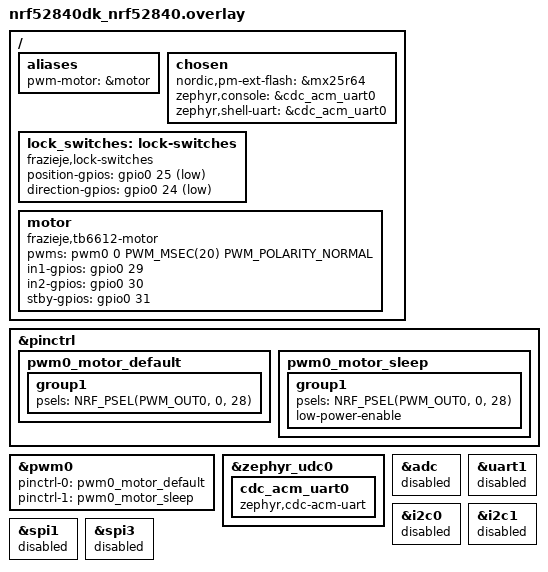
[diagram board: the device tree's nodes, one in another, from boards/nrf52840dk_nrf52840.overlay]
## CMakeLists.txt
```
#
# Copyright (c) 2021 Nordic Semiconductor ASA
#
# SPDX-License-Identifier: LicenseRef-Nordic-5-Clause
#

cmake_minimum_required(VERSION 3.20.0)

find_package(Zephyr REQUIRED HINTS $ENV{ZEPHYR_BASE})
project(farlock3)

# Enable GNU STD support.
include(${ZEPHYR_CONNECTEDHOMEIP_MODULE_DIR}/config/nrfconnect/app/enable-gnu-std.cmake)

# NORDIC SDK APP START

# Include all source files that are located in the Matter common directory.
include(${ZEPHYR_NRF_MODULE_DIR}/samples/matter/common/cmake/source_common.cmake)

# Include Data Model utils
include(${ZEPHYR_NRF_MODULE_DIR}/samples/matter/common/cmake/data_model.cmake)

include(${ZEPHYR_NRF_MODULE_DIR}/samples/matter/common/cmake/zap_helpers.cmake)
ncs_get_zap_parent_dir(ZAP_PARENT_DIR)

target_include_directories(app PRIVATE
  src
  ${ZAP_PARENT_DIR}
)

target_sources(app PRIVATE
  src/main.cpp
  src/app_task.cpp
  src/bolt_lock_manager.cpp
  src/indication.cpp
  src/zcl_callbacks.cpp
  src/nfc.c
  src/ndef_storage.c
  src/access/access_data_types.cpp
  src/access/access_manager_credentials.cpp
  src/access/access_manager_users.cpp
  src/access/access_manager.cpp
)

if(NOT CONFIG_FARLOCK3_LOCK_SIMULATED)
  target_sources(app PRIVATE src/lock_hw.c)
endif()

target_sources_ifdef(CONFIG_FARLOCK3_USB_CONSOLE app PRIVATE
  src/usb.c
)

target_sources_ifdef(CONFIG_SHELL app PRIVATE
  src/lock_shell.cpp
)

target_sources_ifdef(CONFIG_LOCK_ACCESS_STORAGE_PERSISTENT_STORAGE app PRIVATE
  src/access/access_storage.cpp
)

target_sources_ifdef(CONFIG_LOCK_ACCESS_STORAGE_PROTECTED_STORAGE app PRIVATE
  src/access/access_storage_psa_ps.cpp
)

target_sources_ifdef(CONFIG_LOCK_SCHEDULES app PRIVATE
  src/access/access_manager_schedules.cpp
)

target_sources_ifdef(CONFIG_LOCK_PRINT_STORAGE_STATUS app PRIVATE
  src/access/access_storage_print.cpp
)

# Do not treat warnings as errors while the variable may be uninitialized for this sample data model.
# In the door-lock-server implementation, there is a warning that the C++ "optional"
# variable may be uninitialized, but actually, it is wrongly interpreted by the Zephyr toolchain.
target_compile_options(matter-data-model PRIVATE -Wno-error=maybe-uninitialized)

ncs_configure_data_model()

# NORDIC SDK APP END
```

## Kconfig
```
#
# Copyright (c) 2021 Nordic Semiconductor
#
# SPDX-License-Identifier: LicenseRef-Nordic-5-Clause
#

mainmenu "FARLock v3 Matter door lock"

menu "FARLock hardware"

config FARLOCK3_LOCK_SIMULATED
	bool "Simulate the bolt (no motor or switches)"
	help
	  Build without the motor driver and switch handling. Lock and unlock
	  actions complete after a fixed delay. Useful on development kits
	  without the mechanism attached. When disabled, the board must provide
	  "frazieje,tb6612-motor" and "frazieje,lock-switches" devicetree nodes.

if !FARLOCK3_LOCK_SIMULATED

config FARLOCK3_MOTOR_TIMEOUT_MS
	int "Maximum motor run time in milliseconds"
	default 3000
	help
	  The motor is stopped when the bolt position switch changes. If that
	  has not happened after this many milliseconds the motor is stopped
	  anyway and a LockJammed alarm is raised.

config FARLOCK3_MOTOR_DUTY_CYCLE
	int "Motor PWM duty cycle in percent"
	range 1 100
	default 100

config FARLOCK3_SWITCH_DEBOUNCE_MS
	int "Position switch debounce time in milliseconds"
	default 20

endif # !FARLOCK3_LOCK_SIMULATED

config FARLOCK3_USB_CONSOLE
	bool "USB CDC ACM console"
	default y
	depends on USB_DEVICE_STACK_NEXT && USBD_CDC_ACM_CLASS
	help
	  Bring up the USB device stack at boot so that the console and shell
	  are available over the micro-B port when a host is attached.

if FARLOCK3_USB_CONSOLE

config FARLOCK3_USBD_VID
	hex "USB vendor ID"
	default 0x1915

config FARLOCK3_USBD_PID
	hex "USB product ID"
	default 0x0004

config FARLOCK3_USBD_MANUFACTURER
	string "USB manufacturer string"
	default "frazieje"

config FARLOCK3_USBD_PRODUCT
	string "USB product string"
	default "FARLock v3"

config FARLOCK3_USBD_SELF_POWERED
	bool "USB self-powered attribute"
	default y

config FARLOCK3_USBD_REMOTE_WAKEUP
	bool "USB remote wakeup attribute"
	default n

config FARLOCK3_USBD_MAX_POWER
	int "USB maximum power in 2 mA units"
	default 125
	range 0 250

config FARLOCK3_USBD_20_EXTENSION_DESC
	bool "Use default USB 2.0 Extension Descriptor"
	depends on USBD_BOS_SUPPORT

endif # FARLOCK3_USB_CONSOLE

endmenu

menu "Door lock cluster"

config LOCK_MAX_NUM_USERS
	int "Maximum number of users supported by the lock"
	default 10

config LOCK_MAX_NUM_CREDENTIALS_PER_USER
	int "Maximum total number of credentials per one user supported by the lock"
	default 4

config LOCK_MAX_NUM_CREDENTIALS_PER_TYPE
	int "Maximum number of credentials of given type supported by the lock"
	default 15

config LOCK_MAX_CREDENTIAL_LENGTH
	int "Maximum length of the single credential supported by the lock"
	default 10

config LOCK_PASS_CREDENTIALS_TO_SET_LOCK_STATE
	bool "Pass used credentials when setting the lock state"
	help
	  This option should stay disabled until TC-DRLK-2.3 is fixed.
	  Related issue: https://github.com/project-chip/connectedhomeip/issues/38222

config LOCK_SCHEDULES
	bool "Support for WeekDay, YearDay and Holiday schedules in lock"
	help
	  This option adds support for an optional Timed Schedule Access Lock feature.
	  You can use Week Day, Year Day and Holiday schedules to restrict access for a
	  specific user for a defined time window. For example, use it to
	  give the user access only for three days in week.

if LOCK_SCHEDULES

config LOCK_MAX_WEEKDAY_SCHEDULES_PER_USER
	int "Maximum number of WeekDay schedules per one user supported by the lock"
	default 5

config LOCK_MAX_YEARDAY_SCHEDULES_PER_USER
	int "Maximum number of YearDay schedules per one user supported by the lock"
	default 5

config LOCK_MAX_HOLIDAY_SCHEDULES
	int "Maximum number of Holiday schedules supported by the lock"
	default 5

endif

config LOCK_ENABLE_DEBUG
	bool "Debug features to print users and credentials"
	depends on SHELL
	help
	  Debug features allows to checking and printing current users, their state, and
	  associated credentials. Use these with shell commands combinations to read saved credentials
	  or users, and manage them (add, clear, read).

if LOCK_ENABLE_DEBUG

config LOCK_PRINT_STORAGE_STATUS
	bool "Print storage status after each store call"
	# This feature assumes that items are eventually stored in Zephyr settings subsystem
	depends on LOCK_ACCESS_STORAGE_PERSISTENT_STORAGE || TRUSTED_STORAGE_STORAGE_BACKEND_SETTINGS
	help
	  Debug feature to print the debug-level log that contains information of the entry being stored
	  to persistent storage and how many bytes are left to store the new entry. It can be used to verify
	  whether credential, schedule or user entries are written properly to persistent storage.
	  This option should be disabled in production firmware
	  version.

# This should be deterined based on the maximum possible command length that depends on the LOCK_MAX_CREDENTIAL_LENGTH
config SHELL_CMD_BUFF_SIZE
	default 300

endif

choice LOCK_ACCESS_STORAGE_CHOICE
	prompt "Access storage implementation"
	default LOCK_ACCESS_STORAGE_PROTECTED_STORAGE

config LOCK_ACCESS_STORAGE_PERSISTENT_STORAGE
	bool "Persistent storage interface"
	select NCS_SAMPLE_MATTER_PERSISTENT_STORAGE

config LOCK_ACCESS_STORAGE_PROTECTED_STORAGE
	bool "PSA Protected Storage"
	# PSA SSF Crypto Client is not ready for PSA PS backend
	depends on !CHIP_WIFI && !PSA_SSF_CRYPTO_CLIENT
	# When building with TF-M, Protected Storage is enabled by default
	select TRUSTED_STORAGE if !BUILD_WITH_TFM
	select PSA_PROTECTED_STORAGE if !BUILD_WITH_TFM

endchoice

# Increase the storage capacity if the schedules are enabled with secure storage
# This also implies increasing of the OT and Matter stacks because some operations
# performed during commissioning seem to allocate stack buffers based on the
# maximum possible secure asset size.
if LOCK_SCHEDULES && NCS_SAMPLE_MATTER_SECURE_STORAGE_BACKEND

config NCS_SAMPLE_MATTER_SECURE_STORAGE_MAX_ENTRY_NUMBER
	default 128

config TRUSTED_STORAGE_BACKEND_AEAD_MAX_DATA_SIZE
	default 3072

config OPENTHREAD_THREAD_STACK_SIZE
	default 7168

config CHIP_TASK_STACK_SIZE
	default 10240

config MAIN_STACK_SIZE
	default 7168

endif

if LOCK_ACCESS_STORAGE_PROTECTED_STORAGE

config LOCK_ACCESS_STORAGE_PROTECTED_STORAGE_UID_OFFSET
	int "Access storage PSA Protected Storage UID range start"
	default 0

endif # LOCK_ACCESS_STORAGE_PROTECTED_STORAGE

endmenu

config STATE_LEDS
	bool "Use LEDs to indicate the device state"
	default y
	help
	  Use LEDs to render the current state of the device such as the progress of commissioning of
	  the device into a network or the factory reset initiation. Note that setting this option to
	  'n' does not disable the LED indicating the state of the simulated bolt.

# Thread networking: sleepy end device
if OPENTHREAD

# Build OpenThread from source instead of Nordic's prebuilt MTD library. The
# prebuilt library has a fixed feature set; options such as the periodic
# parent search below are silently ignored unless the stack is compiled here.
choice OPENTHREAD_IMPLEMENTATION
	default OPENTHREAD_SOURCES
endchoice

choice OPENTHREAD_NORDIC_LIBRARY_CONFIGURATION
	default OPENTHREAD_NORDIC_LIBRARY_MTD
endchoice

choice OPENTHREAD_DEVICE_TYPE
	default OPENTHREAD_MTD
endchoice

config CHIP_ENABLE_ICD_SUPPORT
	default y

# Thread TX output power. The nRF52840 tops out at +8 dBm. A sleepy end device
# only transmits for a fraction of a millisecond per poll, so the extra current
# is lost in the sleep floor, while the 8 dB of margin matters when the lock is
# mounted on a steel door across a few walls from the border router.
config OPENTHREAD_DEFAULT_TX_POWER
	default 8

# Periodic parent search. A sleepy end device otherwise keeps its parent until
# that link fails outright, so a lock that attached straight to the border
# router never moves to a closer Thread router added later. With this on it
# re-evaluates every CHECK_INTERVAL (9 min) while the parent's RSS is below
# RSS_THRESHOLD (-65 dBm) and backs off BACKOFF_INTERVAL (10 h) after a search.
config OPENTHREAD_PARENT_SEARCH
	default y

endif # OPENTHREAD

source "$(ZEPHYR_CONNECTEDHOMEIP_MODULE_DIR)/config/nrfconnect/chip-module/Kconfig.features"
source "$(ZEPHYR_CONNECTEDHOMEIP_MODULE_DIR)/config/nrfconnect/chip-module/Kconfig.defaults"
source "$(ZEPHYR_NRF_MODULE_DIR)/samples/matter/common/src/Kconfig"
source "Kconfig.zephyr"
```

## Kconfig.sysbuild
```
#
# Copyright (c) 2023 Nordic Semiconductor ASA
#
# SPDX-License-Identifier: LicenseRef-Nordic-5-Clause
#

#### Bootloader
choice BOOTLOADER
	default BOOTLOADER_MCUBOOT
endchoice

if BOOTLOADER_MCUBOOT

#### DFU multi-image support
config DFU_MULTI_IMAGE_PACKAGE_BUILD
	default y

config DFU_MULTI_IMAGE_PACKAGE_APP
	default y

# Secondary slot lives in the MX25R64 QSPI flash
config PM_EXTERNAL_FLASH_MCUBOOT_SECONDARY
	default y

endif # BOOTLOADER_MCUBOOT

#### Enable generating factory data
config MATTER_FACTORY_DATA_GENERATE
	default y

source "share/sysbuild/Kconfig"
```

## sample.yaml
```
sample:
  description: FARLock v3 Matter over Thread door lock
  name: farlock3
common:
  sysbuild: true
  build_only: true
  platform_allow:
    - farlock3
    - nrf52840dk/nrf52840
  integration_platforms:
    - farlock3
  tags:
    - sysbuild
    - matter
tests:
  app.farlock3.debug: {}
  app.farlock3.release:
    extra_args:
      - FILE_SUFFIX=release
  app.farlock3.schedules:
    extra_args:
      - EXTRA_CONF_FILE=schedules.conf
  app.farlock3.simulated:
    extra_args:
      - CONFIG_FARLOCK3_LOCK_SIMULATED=y
```

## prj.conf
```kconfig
#
# FARLock v3 debug configuration (console, shell, logging enabled).
# Matter defaults come from Kconfig.defaults; only overrides live here.
#

# Enable CHIP
CONFIG_CHIP=y
CONFIG_CHIP_PROJECT_CONFIG="src/chip_project_config.h"
CONFIG_CHIP_DEVICE_PRODUCT_NAME="FAR Door Lock v3"

# Configure ZAP file name
CONFIG_NCS_SAMPLE_MATTER_ZAP_FILE_PATH="${APPLICATION_CONFIG_DIR}/src/default_zap/lock.zap"

# 32774 == 0x8006 (example lock-app)
CONFIG_CHIP_DEVICE_PRODUCT_ID=32774
CONFIG_STD_CPP17=y

# Enable Matter extended announcement and increase duration to 1 hour.
CONFIG_CHIP_BLE_EXT_ADVERTISING=y
CONFIG_CHIP_BLE_ADVERTISING_DURATION=60

# LEDs and buttons through the Nordic board layer
CONFIG_DK_LIBRARY=y

# Bluetooth Low Energy configuration
CONFIG_BT_DEVICE_NAME="FARLock3"

# Suspend devices when the CPU goes into sleep
CONFIG_PM_DEVICE=y

# Motor driver
CONFIG_PWM=y

# NFC: the application owns the NFCT peripheral as a writable Type 4 Tag, so
# Matter's Type 2 Tag onboarding payload must stay off.
CONFIG_CHIP_NFC_ONBOARDING_PAYLOAD=n
CONFIG_NFC_T4T_NRFXLIB=y
CONFIG_NFC_NDEF=y
CONFIG_NFC_NDEF_MSG=y
CONFIG_NDEF_FILE_SIZE=256

# USB CDC ACM console (new USB device stack)
CONFIG_USB_DEVICE_STACK_NEXT=y
CONFIG_USBD_CDC_ACM_CLASS=y
CONFIG_CDC_ACM_SERIAL_INITIALIZE_AT_BOOT=n
CONFIG_UART_LINE_CTRL=y
CONFIG_UART_INTERRUPT_DRIVEN=y
CONFIG_FARLOCK3_USBD_PRODUCT="FARLock v3"

# Firmware update. DFU over Bluetooth LE SMP (nRF Connect Device Manager app):
# a program-button press starts the SMP service, the image goes to the QSPI
# secondary slot and MCUboot swaps it in. The retention boot mode lets the
# application reboot straight into MCUboot's USB serial recovery.
CONFIG_CHIP_DFU_OVER_BT_SMP=y
CONFIG_RETAINED_MEM=y
CONFIG_RETENTION=y
CONFIG_RETENTION_BOOT_MODE=y
CONFIG_REBOOT=y

# Firmware version. Bump both lines together for every release: MCUboot and
# the Bluetooth/USB update tools compare the image version, Matter OTA
# compares the software version (integer must increase).
CONFIG_MCUBOOT_IMGTOOL_SIGN_VERSION="0.1.3+4"
CONFIG_CHIP_DEVICE_SOFTWARE_VERSION=4
CONFIG_CHIP_DEVICE_SOFTWARE_VERSION_STRING="0.1.3"
# Lets MCUmgr clients learn the buffer size and use large chunks (faster DFU).
CONFIG_MCUMGR_GRP_OS_MCUMGR_PARAMS=y

# Shell
CONFIG_SHELL=y
CONFIG_OPENTHREAD_SHELL=y
CONFIG_CHIP_LIB_SHELL=y
CONFIG_NCS_SAMPLE_MATTER_TEST_SHELL=y
# Bench verification of the external QSPI flash. The app suspends the flash
# at boot (ExternalFlashManager SLEEP), so resume it with the PM shell before
# using the flash shell: pm resume mx25r6435f@0
CONFIG_FLASH_SHELL=y
CONFIG_PM_DEVICE_SHELL=y

# Other settings
CONFIG_THREAD_NAME=y
CONFIG_MPU_STACK_GUARD=y
CONFIG_RESET_ON_FATAL_ERROR=n

# Reduce application size
CONFIG_USE_SEGGER_RTT=n
CONFIG_MATTER_LOG_LEVEL_INF=y
CONFIG_CHIP_APP_LOG_LEVEL=3

# Enable Factory Data feature
CONFIG_CHIP_FACTORY_DATA=y
CONFIG_CHIP_FACTORY_DATA_BUILD=y
```

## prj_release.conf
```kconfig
#
# FARLock v3 release configuration: no console, no USB, no logging, watchdog on.
# Matter defaults come from Kconfig.defaults; only overrides live here.
#

# Enable CHIP
CONFIG_CHIP=y
CONFIG_CHIP_PROJECT_CONFIG="src/chip_project_config.h"
CONFIG_CHIP_DEVICE_PRODUCT_NAME="FAR Door Lock v3"

# Configure ZAP file name
CONFIG_NCS_SAMPLE_MATTER_ZAP_FILE_PATH="${APPLICATION_CONFIG_DIR}/src/default_zap/lock.zap"

# 32774 == 0x8006 (example lock-app)
CONFIG_CHIP_DEVICE_PRODUCT_ID=32774
CONFIG_STD_CPP17=y

# Matter extended announcement; the commissioning window lasts 15 minutes.
CONFIG_CHIP_BLE_EXT_ADVERTISING=y
CONFIG_CHIP_BLE_ADVERTISING_DURATION=15

# LEDs and buttons through the Nordic board layer. The LED language lives in
# src/indication.h: nothing is lit in steady state.
CONFIG_DK_LIBRARY=y

# Bluetooth Low Energy configuration
CONFIG_BT_DEVICE_NAME="FARLock3"

# Suspend devices when the CPU goes into sleep
CONFIG_PM_DEVICE=y

# Motor driver
CONFIG_PWM=y

# NFC: writable Type 4 Tag owned by the application
CONFIG_CHIP_NFC_ONBOARDING_PAYLOAD=n
CONFIG_NFC_T4T_NRFXLIB=y
CONFIG_NFC_NDEF=y
CONFIG_NFC_NDEF_MSG=y
CONFIG_NDEF_FILE_SIZE=256

# No USB, no console
CONFIG_USB_DEVICE_STACK_NEXT=n
CONFIG_USBD_CDC_ACM_CLASS=n

# Firmware update. DFU over Bluetooth LE SMP (nRF Connect Device Manager app):
# a program-button press starts the SMP service, the image goes to the QSPI
# secondary slot and MCUboot swaps it in. The retention boot mode lets the
# application reboot straight into MCUboot's USB serial recovery.
CONFIG_CHIP_DFU_OVER_BT_SMP=y
CONFIG_RETAINED_MEM=y
CONFIG_RETENTION=y
CONFIG_RETENTION_BOOT_MODE=y
CONFIG_REBOOT=y

# Firmware version. Bump both lines together for every release: MCUboot and
# the Bluetooth/USB update tools compare the image version, Matter OTA
# compares the software version (integer must increase).
CONFIG_MCUBOOT_IMGTOOL_SIGN_VERSION="0.1.3+4"
CONFIG_CHIP_DEVICE_SOFTWARE_VERSION=4
CONFIG_CHIP_DEVICE_SOFTWARE_VERSION_STRING="0.1.3"
# Lets MCUmgr clients learn the buffer size and use large chunks (faster DFU).
CONFIG_MCUMGR_GRP_OS_MCUMGR_PARAMS=y

# Enable system reset on fatal error
CONFIG_RESET_ON_FATAL_ERROR=y

# Try to disable unused RAM blocks to reduce power consumption
CONFIG_RAM_POWER_DOWN_LIBRARY=y

# Disable all debug features
CONFIG_USE_SEGGER_RTT=n
CONFIG_SHELL=n
CONFIG_OPENTHREAD_SHELL=n
CONFIG_CONSOLE=n
CONFIG_UART_CONSOLE=n
CONFIG_SERIAL=n
CONFIG_LOG=n
CONFIG_LOG_MODE_MINIMAL=n
CONFIG_ASSERT_VERBOSE=n
CONFIG_ASSERT_NO_FILE_INFO=y
CONFIG_PRINTK=n
CONFIG_PRINTK_SYNC=n
CONFIG_THREAD_NAME=n
CONFIG_BOOT_BANNER=n

# Enable Factory Data feature
CONFIG_CHIP_FACTORY_DATA=y
CONFIG_CHIP_FACTORY_DATA_BUILD=y

# Enable Watchdog
CONFIG_NCS_SAMPLE_MATTER_WATCHDOG=y

# Enable LTO to decrease the flash usage.
CONFIG_LTO=y
CONFIG_ISR_TABLES_LOCAL_DECLARATION=y
```

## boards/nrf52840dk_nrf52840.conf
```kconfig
CONFIG_SERIAL=y

# enable console
CONFIG_CONSOLE=y
CONFIG_UART_CONSOLE=y
CONFIG_UART_INTERRUPT_DRIVEN=y
CONFIG_UART_LINE_CTRL=y

# Enable USB
CONFIG_USB_DEVICE_STACK_NEXT=y
CONFIG_USBD_CDC_ACM_CLASS=y
CONFIG_CDC_ACM_SERIAL_INITIALIZE_AT_BOOT=n
```

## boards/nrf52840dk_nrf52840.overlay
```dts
/*
 * nRF52840 DK bench configuration for FARLock v3 firmware.
 *
 * Mirrors the farlock3 board: console on USB CDC ACM, motor driver on the
 * same pins as the real board (P0.28 to P0.31, available on the Arduino
 * header) and the bolt switches on DK buttons 3 and 4 (P0.24 / P0.25). Button
 * 1 is the program button, button 2 toggles the bolt.
 *
 * SPDX-License-Identifier: Apache-2.0
 */

#include <zephyr/dt-bindings/pwm/pwm.h>

/* Buttons 3 and 4 become the lock switches; keep them out of the polled buttons node. */
/ {
	aliases {
		/delete-property/ sw2;
		/delete-property/ sw3;
	};
};
/delete-node/ &button2;
/delete-node/ &button3;

/ {
	chosen {
		nordic,pm-ext-flash = &mx25r64;
		zephyr,console = &cdc_acm_uart0;
		zephyr,shell-uart = &cdc_acm_uart0;
	};

	lock_switches: lock-switches {
		compatible = "frazieje,lock-switches";
		/* DK button 4 */
		position-gpios = <&gpio0 25 (GPIO_PULL_UP | GPIO_ACTIVE_LOW)>;
		/* DK button 3 */
		direction-gpios = <&gpio0 24 (GPIO_PULL_UP | GPIO_ACTIVE_LOW)>;
	};

	motor: motor {
		compatible = "frazieje,tb6612-motor";
		pwms = <&pwm0 0 PWM_MSEC(20) PWM_POLARITY_NORMAL>;
		in1-gpios = <&gpio0 29 GPIO_ACTIVE_HIGH>;
		in2-gpios = <&gpio0 30 GPIO_ACTIVE_HIGH>;
		stby-gpios = <&gpio0 31 GPIO_ACTIVE_HIGH>;
	};

	aliases {
		pwm-motor = &motor;
	};
};

&pinctrl {
	pwm0_motor_default: pwm0_motor_default {
		group1 {
			psels = <NRF_PSEL(PWM_OUT0, 0, 28)>;
		};
	};

	pwm0_motor_sleep: pwm0_motor_sleep {
		group1 {
			psels = <NRF_PSEL(PWM_OUT0, 0, 28)>;
			low-power-enable;
		};
	};
};

&pwm0 {
	status = "okay";
	pinctrl-0 = <&pwm0_motor_default>;
	pinctrl-1 = <&pwm0_motor_sleep>;
	pinctrl-names = "default", "sleep";
};

&zephyr_udc0 {
	cdc_acm_uart0: cdc_acm_uart0 {
		compatible = "zephyr,cdc-acm-uart";
	};
};

/* Disable unused peripherals to reduce power consumption */
&adc {
	status = "disabled";
};

&uart1 {
	status = "disabled";
};

&i2c0 {
	status = "disabled";
};

&i2c1 {
	status = "disabled";
};

&spi1 {
	status = "disabled";
};

&spi3 {
	status = "disabled";
};
```

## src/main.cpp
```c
/*
 * Copyright (c) 2021 Nordic Semiconductor ASA
 *
 * SPDX-License-Identifier: LicenseRef-Nordic-5-Clause
 */

#include "app_task.h"

#ifdef CONFIG_FARLOCK3_USB_CONSOLE
#include "usb.h"
#endif

#include <zephyr/logging/log.h>

LOG_MODULE_REGISTER(app, CONFIG_CHIP_APP_LOG_LEVEL);

int main()
{
#ifdef CONFIG_FARLOCK3_USB_CONSOLE
	int ret = start_usb();
	if (ret) {
		LOG_INF("USB host not detected (%d), continuing without console", ret);
	}
#endif

	CHIP_ERROR err = AppTask::Instance().StartApp();

	LOG_ERR("Exited with code %" CHIP_ERROR_FORMAT, err.Format());
	return err == CHIP_NO_ERROR ? EXIT_SUCCESS : EXIT_FAILURE;
}
```

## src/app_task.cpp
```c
/*
 * Copyright (c) 2021 Nordic Semiconductor ASA
 *
 * SPDX-License-Identifier: LicenseRef-Nordic-5-Clause
 */

#include "app_task.h"
#include "bolt_lock_manager.h"
#include "clusters/identify.h"
#include "indication.h"
#include "nfc.h"

#include "app/matter_init.h"
#include "app/task_executor.h"

#include <app-common/zap-generated/attributes/Accessors.h>
#include <app/clusters/door-lock-server/door-lock-server.h>
#include <platform/CHIPDeviceLayer.h>
#include <setup_payload/OnboardingCodesUtil.h>

#include <dk_buttons_and_leds.h>
#include <zephyr/devicetree.h>
#include <zephyr/kernel.h>
#include <zephyr/logging/log.h>

LOG_MODULE_DECLARE(app, CONFIG_CHIP_APP_LOG_LEVEL);

using namespace ::chip;
using namespace ::chip::app;
using namespace ::chip::DeviceLayer;

namespace
{
constexpr EndpointId kLockEndpointId = 1;

/*
 * A second push button toggles the bolt for bench testing on development kits.
 * The real board only has the program button, which the Nordic board layer
 * uses for commissioning and factory reset.
 */
#if DT_NODE_EXISTS(DT_NODELABEL(button1))
#define APPLICATION_BUTTON_MASK DK_BTN2_MSK
#endif

#ifndef CONFIG_CHIP_FACTORY_RESET_ERASE_SETTINGS
void AppFactoryResetHandler(const ChipDeviceEvent *event, intptr_t /* unused */)
{
	switch (event->Type) {
	case DeviceEventType::kFactoryReset:
		BoltLockMgr().FactoryReset();
		break;
	default:
		break;
	}
}
#endif

Nrf::Matter::IdentifyCluster sIdentifyCluster(kLockEndpointId, false, []() {
	Nrf::PostTask([] { Indication::IdentifyDone(); });
});
} /* namespace */

void AppTask::ButtonEventHandler(Nrf::ButtonState state, Nrf::ButtonMask hasChanged)
{
	/*
	 * Program button. The board layer owns its functions (advertising, DFU,
	 * factory reset); this only adds the on-demand connectivity flash for a
	 * short press on a commissioned lock. Longer holds are the factory-reset
	 * sequence and already blink every LED.
	 */
	static int64_t pressedAt;

	if (hasChanged & DK_BTN1_MSK) {
		if (state & DK_BTN1_MSK) {
			pressedAt = k_uptime_get();
		} else if (k_uptime_get() - pressedAt < Nrf::FactoryResetConsts::kFactoryResetTriggerTimeout) {
			Nrf::PostTask([] {
				if (chip::DeviceLayer::ConnectivityMgr().IsThreadProvisioned()) {
					Indication::ButtonTap(chip::DeviceLayer::ConnectivityMgr().IsThreadAttached());
				}
			});
		}
	}

#ifdef APPLICATION_BUTTON_MASK
	if ((APPLICATION_BUTTON_MASK & hasChanged) & state) {
		Nrf::PostTask([] { LockActionEventHandler(); });
	}
#endif
}

void AppTask::LockActionEventHandler()
{
	if (BoltLockMgr().IsLocked()) {
		BoltLockMgr().Unlock(BoltLockManager::OperationSource::kButton);
	} else {
		BoltLockMgr().Lock(BoltLockManager::OperationSource::kButton);
	}
}

void AppTask::LockStateChanged(const BoltLockManager::StateData &stateData)
{
	switch (stateData.mState) {
	case BoltLockManager::State::kLockingInitiated:
		LOG_INF("Lock action initiated");
		Indication::LockOperationStarted(true);
		break;
	case BoltLockManager::State::kLockingCompleted:
		LOG_INF("Lock action completed");
		Indication::LockOperationCompleted(true);
		break;
	case BoltLockManager::State::kUnlockingInitiated:
		LOG_INF("Unlock action initiated");
		Indication::LockOperationStarted(false);
		break;
	case BoltLockManager::State::kUnlockingCompleted:
		LOG_INF("Unlock action completed");
		Indication::LockOperationCompleted(false);
		break;
	}

	/* Handle changing attribute state in the application */
	Instance().UpdateClusterState(stateData);
}

void AppTask::UpdateClusterState(const BoltLockManager::StateData &stateData)
{
	BoltLockManager::StateData *stateDataCopy = Platform::New<BoltLockManager::StateData>(stateData);

	if (stateDataCopy == nullptr) {
		LOG_ERR("Failed to allocate memory for BoltLockManager::StateData");
		return;
	}

	CHIP_ERROR err = SystemLayer().ScheduleLambda([stateDataCopy]() {
		UpdateClusterStateHandler(*stateDataCopy);
		Platform::Delete(stateDataCopy);
	});

	if (err != CHIP_NO_ERROR) {
		LOG_ERR("Failed to schedule lambda: %" CHIP_ERROR_FORMAT, err.Format());
		Platform::Delete(stateDataCopy);
	}
}

void AppTask::UpdateClusterStateHandler(const BoltLockManager::StateData &stateData)
{
	using namespace chip::app::Clusters::DoorLock::Attributes;

	DlLockState newLockState;

	switch (stateData.mState) {
	case BoltLockManager::State::kLockingCompleted:
		newLockState = DlLockState::kLocked;
		break;
	case BoltLockManager::State::kUnlockingCompleted:
		newLockState = DlLockState::kUnlocked;
		break;
	default:
		newLockState = DlLockState::kNotFullyLocked;
		break;
	}

	Nullable<DlLockState> currentLockState;
	LockState::Get(kLockEndpointId, currentLockState);

	if (currentLockState.IsNull()) {
		/* Initialize lock state with start value, but not invoke lock/unlock. */
		LockState::Set(kLockEndpointId, newLockState);
	} else {
		LOG_INF("Updating LockState attribute");

		Nullable<uint16_t> userId;
		Nullable<List<const LockOpCredentials>> credentials;
#ifdef CONFIG_LOCK_PASS_CREDENTIALS_TO_SET_LOCK_STATE
		List<const LockOpCredentials> credentialList;
#endif

		if (!stateData.mValidatePINResult.IsNull()) {
			userId = { stateData.mValidatePINResult.Value().mUserId };

#ifdef CONFIG_LOCK_PASS_CREDENTIALS_TO_SET_LOCK_STATE
			/* `DoorLockServer::SetLockState` exptects list of `LockOpCredentials`,
			   however in case of PIN validation it makes no sense to have more than one
			   credential corresponding to validation result. For simplicity we wrap single
			   credential in list here. */
			credentialList = { &stateData.mValidatePINResult.Value().mCredential, 1 };
			credentials = { credentialList };
#endif
		}

		if (!DoorLockServer::Instance().SetLockState(kLockEndpointId, newLockState, stateData.mSource, userId,
							     credentials, stateData.mFabricIdx, stateData.mNodeId)) {
			LOG_ERR("Failed to update LockState attribute");
		}
	}
}

void AppTask::ReportLockJammed()
{
	Indication::LockJammed();

	CHIP_ERROR err = SystemLayer().ScheduleLambda([]() {
		if (!DoorLockServer::Instance().SendLockAlarmEvent(kLockEndpointId, AlarmCodeEnum::kLockJammed)) {
			LOG_ERR("Failed to send LockJammed alarm event");
		}
	});

	if (err != CHIP_NO_ERROR) {
		LOG_ERR("Failed to schedule LockJammed alarm: %" CHIP_ERROR_FORMAT, err.Format());
	}
}

#ifdef CONFIG_NCS_SAMPLE_MATTER_TEST_EVENT_TRIGGERS
CHIP_ERROR AppTask::DoorLockJammedEventCallback(Nrf::Matter::TestEventTrigger::TriggerValue)
{
	VerifyOrReturnError(DoorLockServer::Instance().SendLockAlarmEvent(kLockEndpointId, AlarmCodeEnum::kLockJammed),
			    CHIP_ERROR_INTERNAL);
	LOG_ERR("Event Trigger: Doorlock jammed.");
	return CHIP_NO_ERROR;
}
#endif

CHIP_ERROR AppTask::Init()
{
	/* Initialize Matter stack */
	ReturnErrorOnFailure(Nrf::Matter::PrepareServer());

	if (!Nrf::GetBoard().Init(ButtonEventHandler, Indication::StatusLedHandler)) {
		LOG_ERR("User interface initialization failed.");
		return CHIP_ERROR_INCORRECT_STATE;
	}

	/* Register Matter event handler that tracks the network state for the connection LED (see indication.h). */
	ReturnErrorOnFailure(Nrf::Matter::RegisterEventHandler(Nrf::Board::DefaultMatterEventHandler, 0));

#ifndef CONFIG_CHIP_FACTORY_RESET_ERASE_SETTINGS
	/* Register factory reset event handler.
	 * With this configuration we have to manually clean up the storage,
	 * as whole settings partition won't be erased.
	 * */
	ReturnErrorOnFailure(Nrf::Matter::RegisterEventHandler(AppFactoryResetHandler, 0));
#endif

	/* Initialize lock manager (motor, switches, credentials) */
	BoltLockMgr().Init(LockStateChanged);

	/* NFC tag. The settings subsystem is up at this point (PrepareServer initialised it). */
	int nfcErr = nfc_tag_init();
	if (nfcErr) {
		LOG_ERR("NFC tag initialisation failed (%d), continuing without NFC", nfcErr);
	}

	/* Register Door Lock test event trigger */
#ifdef CONFIG_NCS_SAMPLE_MATTER_TEST_EVENT_TRIGGERS
	ReturnErrorOnFailure(Nrf::Matter::TestEventTrigger::Instance().RegisterTestEventTrigger(
		kDoorLockJammedEventTriggerId,
		Nrf::Matter::TestEventTrigger::EventTrigger{ 0, DoorLockJammedEventCallback }));
#endif

	ReturnErrorOnFailure(sIdentifyCluster.Init());

	return Nrf::Matter::StartServer();
}

CHIP_ERROR AppTask::StartApp()
{
	ReturnErrorOnFailure(Init());

	while (true) {
		Nrf::DispatchNextTask();
	}

	return CHIP_NO_ERROR;
}
```

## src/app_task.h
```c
/*
 * Copyright (c) 2021 Nordic Semiconductor ASA
 *
 * SPDX-License-Identifier: LicenseRef-Nordic-5-Clause
 */

#pragma once

#include "board/board.h"
#include "board/led_widget.h"
#include "bolt_lock_manager.h"

struct k_timer;
struct Identify;

#ifdef CONFIG_NCS_SAMPLE_MATTER_TEST_EVENT_TRIGGERS
#include "event_triggers/event_triggers.h"
#endif

class AppTask {
public:
	static AppTask &Instance()
	{
		static AppTask sAppTask;
		return sAppTask;
	};

	CHIP_ERROR StartApp();

	void UpdateClusterState(const BoltLockManager::StateData &stateData);

	/** Emit a Door Lock "LockJammed" alarm event. Safe to call from the application thread. */
	void ReportLockJammed();

private:
	CHIP_ERROR Init();

	static void LockActionEventHandler();
	static void ButtonEventHandler(Nrf::ButtonState state, Nrf::ButtonMask hasChanged);
	static void LockStateChanged(const BoltLockManager::StateData &stateData);
	static void UpdateClusterStateHandler(const BoltLockManager::StateData &stateData);

#ifdef CONFIG_NCS_SAMPLE_MATTER_TEST_EVENT_TRIGGERS
	constexpr static Nrf::Matter::TestEventTrigger::EventTriggerId kDoorLockJammedEventTriggerId =
		0xFFFF'FFF3'2774'0000;
	static CHIP_ERROR DoorLockJammedEventCallback(Nrf::Matter::TestEventTrigger::TriggerValue);
#endif
};
```

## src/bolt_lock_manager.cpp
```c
/*
 * Copyright (c) 2021 Nordic Semiconductor ASA
 *
 * SPDX-License-Identifier: LicenseRef-Nordic-5-Clause
 */

#include "bolt_lock_manager.h"
#include "app/task_executor.h"

#include "app_task.h"

#ifndef CONFIG_FARLOCK3_LOCK_SIMULATED
#include "lock_hw.h"
#endif

#include <zephyr/logging/log.h>

LOG_MODULE_DECLARE(app, CONFIG_CHIP_APP_LOG_LEVEL);

using namespace chip;

namespace
{
#ifdef CONFIG_FARLOCK3_LOCK_SIMULATED
/* Simulated bolt: the "motor" simply takes this long. */
constexpr uint32_t kActuatorTimeoutMs = 2000;
#else
/* Real bolt: give up and report a jam if the position switch has not changed by then. */
constexpr uint32_t kActuatorTimeoutMs = CONFIG_FARLOCK3_MOTOR_TIMEOUT_MS;
#endif
} /* namespace */

BoltLockManager BoltLockManager::sLock;

void BoltLockManager::Init(StateChangeCallback callback)
{
	mStateChangeCallback = callback;

	k_timer_init(&mActuatorTimer, &BoltLockManager::ActuatorTimerEventHandler, nullptr);
	k_timer_user_data_set(&mActuatorTimer, this);

	AccessMgr::Instance().Init();

#ifndef CONFIG_FARLOCK3_LOCK_SIMULATED
	int err = lock_hw_init(SwitchChangedHandler);
	if (err) {
		LOG_ERR("Lock hardware initialisation failed (%d); bolt state is unknown", err);
	} else {
		/* Start from the real position of the bolt rather than assuming "locked". */
		mStateData.mState = lock_hw_is_locked() ? State::kLockingCompleted : State::kUnlockingCompleted;
		mStateData.mSource = OperationSource::kManual;
	}
#endif

}

bool BoltLockManager::GetUser(uint16_t userIndex, EmberAfPluginDoorLockUserInfo &user)
{
	return AccessMgr::Instance().GetUserInfo(userIndex, user);
}

bool BoltLockManager::SetUser(uint16_t userIndex, FabricIndex creator, FabricIndex modifier, const CharSpan &userName,
			      uint32_t uniqueId, UserStatusEnum userStatus, UserTypeEnum userType,
			      CredentialRuleEnum credentialRule, const CredentialStruct *credentials,
			      size_t totalCredentials)
{
	return AccessMgr::Instance().SetUser(userIndex, creator, modifier, userName, uniqueId, userStatus, userType,
					     credentialRule, credentials, totalCredentials);
}

bool BoltLockManager::GetCredential(uint16_t credentialIndex, CredentialTypeEnum credentialType,
				    EmberAfPluginDoorLockCredentialInfo &credential)
{
	return AccessMgr::Instance().GetCredential(credentialIndex, credentialType, credential);
}

bool BoltLockManager::SetCredential(uint16_t credentialIndex, FabricIndex creator, FabricIndex modifier,
				    DlCredentialStatus credentialStatus, CredentialTypeEnum credentialType,
				    const ByteSpan &secret)
{
	return AccessMgr::Instance().SetCredential(credentialIndex, creator, modifier, credentialStatus, credentialType,
						   secret);
}

#ifdef CONFIG_LOCK_SCHEDULES

DlStatus BoltLockManager::GetWeekDaySchedule(uint8_t weekdayIndex, uint16_t userIndex,
					     EmberAfPluginDoorLockWeekDaySchedule &schedule)
{
	return AccessMgr::Instance().GetWeekDaySchedule(weekdayIndex, userIndex, schedule);
}

DlStatus BoltLockManager::SetWeekDaySchedule(uint8_t weekdayIndex, uint16_t userIndex, DlScheduleStatus status,
					     DaysMaskMap daysMask, uint8_t startHour, uint8_t startMinute,
					     uint8_t endHour, uint8_t endMinute)
{
	return AccessMgr::Instance().SetWeekDaySchedule(weekdayIndex, userIndex, status, daysMask, startHour,
							startMinute, endHour, endMinute);
}

DlStatus BoltLockManager::GetYearDaySchedule(uint8_t yearDayIndex, uint16_t userIndex,
					     EmberAfPluginDoorLockYearDaySchedule &schedule)
{
	return AccessMgr::Instance().GetYearDaySchedule(yearDayIndex, userIndex, schedule);
}

DlStatus BoltLockManager::SetYearDaySchedule(uint8_t yeardayIndex, uint16_t userIndex, DlScheduleStatus status,
					     uint32_t localStartTime, uint32_t localEndTime)
{
	return AccessMgr::Instance().SetYearDaySchedule(yeardayIndex, userIndex, status, localStartTime, localEndTime);
}

DlStatus BoltLockManager::GetHolidaySchedule(uint8_t holidayIndex, EmberAfPluginDoorLockHolidaySchedule &schedule)
{
	return AccessMgr::Instance().GetHolidaySchedule(holidayIndex, schedule);
}

DlStatus BoltLockManager::SetHolidaySchedule(uint8_t holidayIndex, DlScheduleStatus status, uint32_t localStartTime,
					     uint32_t localEndTime, OperatingModeEnum operatingMode)
{
	return AccessMgr::Instance().SetHolidaySchedule(holidayIndex, status, localStartTime, localEndTime,
							operatingMode);
}

#endif /* CONFIG_LOCK_SCHEDULES */

bool BoltLockManager::ValidatePIN(const Optional<chip::ByteSpan> &pinCode, OperationErrorEnum &err,
				  Nullable<ValidatePINResult> &result)
{
	return AccessMgr::Instance().ValidatePIN(pinCode, err, result);
}

void BoltLockManager::SetRequirePIN(bool require)
{
	return AccessMgr::Instance().SetRequirePIN(require);
}
bool BoltLockManager::GetRequirePIN()
{
	return AccessMgr::Instance().GetRequirePIN();
}

void BoltLockManager::Lock(const OperationSource source, const Nullable<chip::FabricIndex> &fabricIdx,
			   const Nullable<chip::NodeId> &nodeId, const Nullable<ValidatePINResult> &validatePINResult)
{
	VerifyOrReturn(mStateData.mState != State::kLockingCompleted);
	VerifyOrReturn(!IsActuating(), LOG_WRN("Lock requested while the bolt is moving, ignored"));

	StateData newStateData{ State::kLockingInitiated, source, fabricIdx, nodeId, validatePINResult };
	SetStateData(newStateData);

	StartActuator(true);
}

void BoltLockManager::Unlock(const OperationSource source, const Nullable<chip::FabricIndex> &fabricIdx,
			     const Nullable<chip::NodeId> &nodeId, const Nullable<ValidatePINResult> &validatePINResult)
{
	VerifyOrReturn(mStateData.mState != State::kUnlockingCompleted);
	VerifyOrReturn(!IsActuating(), LOG_WRN("Unlock requested while the bolt is moving, ignored"));

	StateData newStateData{ State::kUnlockingInitiated, source, fabricIdx, nodeId, validatePINResult };
	SetStateData(newStateData);

	StartActuator(false);
}

void BoltLockManager::StartActuator(bool lock)
{
#ifndef CONFIG_FARLOCK3_LOCK_SIMULATED
	enum lock_hw_direction dir = lock_hw_lock_direction();
	if (!lock) {
		dir = lock_hw_opposite(dir);
	}

	int err = lock_hw_motor_run(dir, CONFIG_FARLOCK3_MOTOR_DUTY_CYCLE);
	if (err) {
		LOG_ERR("Failed to start motor (%d)", err);
	}
#else
	ARG_UNUSED(lock);
#endif

	k_timer_start(&mActuatorTimer, K_MSEC(kActuatorTimeoutMs), K_NO_WAIT);
}

void BoltLockManager::ActuatorTimerEventHandler(k_timer *timer)
{
	/*
	 * The timer event handler is called in the context of the system clock ISR.
	 * Post an event to the application task queue to process the event in the
	 * context of the application thread.
	 */

	BoltLockManagerEvent event;
	event.manager = static_cast<BoltLockManager *>(k_timer_user_data_get(timer));
	Nrf::PostTask([event] { ActuatorAppEventHandler(event); });
}

void BoltLockManager::ActuatorAppEventHandler(const BoltLockManagerEvent &event)
{
	BoltLockManager *lock = reinterpret_cast<BoltLockManager *>(event.manager);
	lock->HandleActuatorTimeout();
}

void BoltLockManager::HandleActuatorTimeout()
{
#ifdef CONFIG_FARLOCK3_LOCK_SIMULATED
	switch (mStateData.mState) {
	case State::kLockingInitiated:
		SetState(State::kLockingCompleted);
		break;
	case State::kUnlockingInitiated:
		SetState(State::kUnlockingCompleted);
		break;
	default:
		break;
	}
#else
	(void)lock_hw_motor_stop();

	if (!IsActuating()) {
		return;
	}

	const bool wantedLocked = (mStateData.mState == State::kLockingInitiated);
	const bool isLocked = lock_hw_is_locked();

	if (isLocked == wantedLocked) {
		/* The switch edge was missed but the bolt is where we wanted it. */
		LOG_WRN("Actuator timeout, but the bolt reached the %s position", isLocked ? "locked" : "unlocked");
		SetState(isLocked ? State::kLockingCompleted : State::kUnlockingCompleted);
	} else {
		LOG_ERR("Bolt jammed: motor ran for %u ms without reaching the %s position", kActuatorTimeoutMs,
			wantedLocked ? "locked" : "unlocked");
		SetState(isLocked ? State::kLockingCompleted : State::kUnlockingCompleted);
		AppTask::Instance().ReportLockJammed();
	}
#endif
}

void BoltLockManager::SwitchChangedHandler(enum lock_hw_switch sw, bool /* active */)
{
	/* Runs on the system work queue; move to the application thread. */
	if (sw == LOCK_HW_SW_DIRECTION) {
		Nrf::PostTask([] { sLock.HandleDirectionChanged(); });
	} else {
		Nrf::PostTask([] { sLock.HandlePositionChanged(); });
	}
}

void BoltLockManager::HandlePositionChanged()
{
#ifndef CONFIG_FARLOCK3_LOCK_SIMULATED
	const bool isLocked = lock_hw_is_locked();

	if (IsActuating()) {
		/* The bolt reached the other end position: stop immediately (the debounce already added a delay). */
		k_timer_stop(&mActuatorTimer);
		(void)lock_hw_motor_stop();

		const bool wantedLocked = (mStateData.mState == State::kLockingInitiated);
		if (isLocked != wantedLocked) {
			LOG_WRN("Bolt stopped in the %s position while trying to %s", isLocked ? "locked" : "unlocked",
				wantedLocked ? "lock" : "unlock");
		}
		SetState(isLocked ? State::kLockingCompleted : State::kUnlockingCompleted);
		return;
	}

	/* Not actuating: someone turned the thumb-turn or key by hand. */
	SyncStateFromSwitches("Bolt moved manually");
#endif
}

void BoltLockManager::HandleDirectionChanged()
{
#ifndef CONFIG_FARLOCK3_LOCK_SIMULATED
	LOG_INF("Handedness switch now %s", lock_hw_lock_direction() == LOCK_HW_DIR_RIGHT ? "right" : "left");

	if (IsActuating()) {
		/*
		 * The motor is turning in a direction that just stopped meaning what it
		 * meant. Stop it where it is and let the switches say what that is.
		 */
		k_timer_stop(&mActuatorTimer);
		(void)lock_hw_motor_stop();
		LOG_WRN("Handedness changed while the bolt was moving; motor stopped");
		SetState(lock_hw_is_locked() ? State::kLockingCompleted : State::kUnlockingCompleted);
		return;
	}

	SyncStateFromSwitches("Handedness changed");
#endif
}

void BoltLockManager::SyncStateFromSwitches(const char *why)
{
#ifndef CONFIG_FARLOCK3_LOCK_SIMULATED
	const bool isLocked = lock_hw_is_locked();
	const State newState = isLocked ? State::kLockingCompleted : State::kUnlockingCompleted;

	if (newState != mStateData.mState) {
		LOG_INF("%s: bolt is now %s", why, isLocked ? "locked" : "unlocked");
		SetStateData(StateData{ newState, OperationSource::kManual, {}, {}, {} });
	}
#else
	ARG_UNUSED(why);
#endif
}

void BoltLockManager::SetState(State state)
{
	mStateData.mState = state;

	if (mStateChangeCallback != nullptr) {
		mStateChangeCallback(mStateData);
	}
}

void BoltLockManager::SetStateData(const StateData &stateData)
{
	mStateData = stateData;

	if (mStateChangeCallback != nullptr) {
		mStateChangeCallback(mStateData);
	}
}

void BoltLockManager::FactoryReset()
{
	AccessMgr::Instance().FactoryReset();
}
```

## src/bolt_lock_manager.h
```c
/*
 * Copyright (c) 2021 Nordic Semiconductor ASA
 *
 * SPDX-License-Identifier: LicenseRef-Nordic-5-Clause
 */

#pragma once

#include "access/access_manager.h"
#include "lock_hw.h"

#include <app/clusters/door-lock-server/door-lock-server.h>
#include <lib/core/ClusterEnums.h>

#include <zephyr/kernel.h>

#include <cstdint>

struct BoltLockManagerEvent;

class BoltLockManager {
	using AccessMgr = AccessManager<DoorLockData::PIN>;

public:
	static constexpr size_t kMaxCredentialLength = 128;

	enum class State : uint8_t {
		kLockingInitiated = 0,
		kLockingCompleted,
		kUnlockingInitiated,
		kUnlockingCompleted,
	};

	struct UserData {
		char mName[DOOR_LOCK_USER_NAME_BUFFER_SIZE];
		CredentialStruct mCredentials[CONFIG_LOCK_MAX_NUM_CREDENTIALS_PER_USER];
	};

	struct CredentialData {
		chip::Platform::ScopedMemoryBuffer<uint8_t> mSecret;
	};

	using OperationSource = chip::app::Clusters::DoorLock::OperationSourceEnum;
	using ValidatePINResult = AccessMgr::ValidatePINResult;

	struct StateData {
		State mState;
		OperationSource mSource;
		Nullable<chip::FabricIndex> mFabricIdx;
		Nullable<chip::NodeId> mNodeId;
		Nullable<ValidatePINResult> mValidatePINResult;
	};

	using StateChangeCallback = void (*)(const StateData &);

	void Init(StateChangeCallback callback);

	const StateData &GetState() const { return mStateData; }
	bool IsLocked() const { return mStateData.mState == State::kLockingCompleted; }
	bool IsActuating() const
	{
		return mStateData.mState == State::kLockingInitiated || mStateData.mState == State::kUnlockingInitiated;
	}

	bool GetUser(uint16_t userIndex, EmberAfPluginDoorLockUserInfo &user);
	bool SetUser(uint16_t userIndex, chip::FabricIndex creator, chip::FabricIndex modifier,
		     const chip::CharSpan &userName, uint32_t uniqueId, UserStatusEnum userStatus,
		     UserTypeEnum userType, CredentialRuleEnum credentialRule, const CredentialStruct *credentials,
		     size_t totalCredentials);

	bool GetCredential(uint16_t credentialIndex, CredentialTypeEnum credentialType,
			   EmberAfPluginDoorLockCredentialInfo &credential);
	bool SetCredential(uint16_t credentialIndex, chip::FabricIndex creator, chip::FabricIndex modifier,
			   DlCredentialStatus credentialStatus, CredentialTypeEnum credentialType,
			   const chip::ByteSpan &secret);

#ifdef CONFIG_LOCK_SCHEDULES
	DlStatus GetWeekDaySchedule(uint8_t weekdayIndex, uint16_t userIndex,
				    EmberAfPluginDoorLockWeekDaySchedule &schedule);
	DlStatus SetWeekDaySchedule(uint8_t weekdayIndex, uint16_t userIndex, DlScheduleStatus status,
				    DaysMaskMap daysMask, uint8_t startHour, uint8_t startMinute, uint8_t endHour,
				    uint8_t endMinute);
	DlStatus GetYearDaySchedule(uint8_t yearDayIndex, uint16_t userIndex,
				    EmberAfPluginDoorLockYearDaySchedule &schedule);
	DlStatus SetYearDaySchedule(uint8_t yearDayIndex, uint16_t userIndex, DlScheduleStatus status,
				    uint32_t localStartTime, uint32_t localEndTime);
	DlStatus GetHolidaySchedule(uint8_t holidayIndex, EmberAfPluginDoorLockHolidaySchedule &schedule);
	DlStatus SetHolidaySchedule(uint8_t holidayIndex, DlScheduleStatus status, uint32_t localStartTime,
				    uint32_t localEndTime, OperatingModeEnum operatingMode);
#endif /* CONFIG_LOCK_SCHEDULES */

	bool ValidatePIN(const Optional<chip::ByteSpan> &pinCode, OperationErrorEnum &err,
			 Nullable<ValidatePINResult> &result);

	void Lock(const OperationSource source, const Nullable<chip::FabricIndex> &fabricIdx = NullNullable,
		  const Nullable<chip::NodeId> &nodeId = NullNullable,
		  const Nullable<ValidatePINResult> &validatePINResult = NullNullable);
	void Unlock(const OperationSource source, const Nullable<chip::FabricIndex> &fabricIdx = NullNullable,
		    const Nullable<chip::NodeId> &nodeId = NullNullable,
		    const Nullable<ValidatePINResult> &validatePINResult = NullNullable);

	void SetRequirePIN(bool require);
	bool GetRequirePIN();

	void FactoryReset();

private:
	friend class AppTask;

	void SetState(State state);
	void SetStateData(const StateData &stateData);

	/* Drive the motor towards the locked (lock == true) or unlocked position and arm the timeout. */
	void StartActuator(bool lock);
	/* Motor ran for the full timeout without the position switch changing. */
	void HandleActuatorTimeout();
	/* The position switch changed, either because the motor got there or because someone turned the thumb-turn. */
	void HandlePositionChanged();
	/* The handedness switch was flipped: the same bolt position now means the opposite lock state. */
	void HandleDirectionChanged();
	/* Not actuating: report whatever state the switches describe, as a manual operation if it differs. */
	void SyncStateFromSwitches(const char *why);

	static void ActuatorTimerEventHandler(k_timer *timer);
	static void ActuatorAppEventHandler(const BoltLockManagerEvent &event);
	static void SwitchChangedHandler(enum lock_hw_switch sw, bool active);
	friend BoltLockManager &BoltLockMgr();

	StateData mStateData = { State::kLockingCompleted, OperationSource::kButton, {}, {}, {} };
	StateChangeCallback mStateChangeCallback = nullptr;
	k_timer mActuatorTimer = {};

	static BoltLockManager sLock;
};

inline BoltLockManager &BoltLockMgr()
{
	return BoltLockManager::sLock;
}

struct BoltLockManagerEvent {
	BoltLockManager *manager;
};
```

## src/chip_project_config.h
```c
/*
 * Copyright (c) 2021 Nordic Semiconductor ASA
 *
 * SPDX-License-Identifier: LicenseRef-Nordic-5-Clause
 */

/**
 *    @file
 *          Project configuration overrides for the Matter stack.
 *
 *          Application-specific overrides of the default configuration values
 *          for general CHIP features go here.
 */

#pragma once
```

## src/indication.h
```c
/*
 * FARLock v3 LED indication.
 *
 * Three LEDs: the connection LED (J3), the green "access granted" and the red
 * "access denied" LEDs (J5). The lock lives on a battery, so nothing is lit
 * in steady state: every pattern is started by an event and ends by itself.
 *
 *   locked (any source)        green, one 1 s flash
 *   unlocked (any source)      red, one 1 s flash
 *   motor running              target colour blinks until the bolt arrives
 *   jam                        red and green alternate, five times
 *   NFC tag read               green, one short flash
 *   commissioning advertising  connection LED, short blink once a second
 *   phone connected (BLE)      connection LED, fast blink
 *   joined Thread              connection LED, three quick flashes
 *   button tap, commissioned   connection LED, one flash on Thread, three if not
 *   idle                       everything off
 *
 * The factory-reset warning (all LEDs blinking while the button is held) and
 * the Matter Identify blink come from the nRF Connect SDK board layer.
 *
 * SPDX-License-Identifier: Apache-2.0
 */

#ifndef FARLOCK3_INDICATION_H
#define FARLOCK3_INDICATION_H

#ifdef __cplusplus
namespace Indication
{
/** Hooked into the board layer: Nrf::GetBoard().Init(buttons, StatusLedHandler). */
void StatusLedHandler();

/** The motor started moving the bolt towards locked (true) or unlocked. */
void LockOperationStarted(bool locking);
/** The bolt arrived (motor, thumbturn or key); locked tells which way. */
void LockOperationCompleted(bool locked);
/** The motor timed out without reaching the position switch. */
void LockJammed();
/** Short press of the program button on a commissioned lock. */
void ButtonTap(bool threadAttached);
/** Matter Identify finished; the board layer blinked the green LED. */
void IdentifyDone();
} /* namespace Indication */

extern "C" {
#endif

/** A reader fetched the NDEF message. Callable from interrupt context. */
void indication_nfc_tap(void);

#ifdef __cplusplus
}
#endif

#endif /* FARLOCK3_INDICATION_H */
```

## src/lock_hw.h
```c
/*
 * FARLock v3 bolt hardware: TB6612FNG motor driver and the position and
 * handedness switches.
 *
 * SPDX-License-Identifier: Apache-2.0
 */

#ifndef FARLOCK3_LOCK_HW_H
#define FARLOCK3_LOCK_HW_H

#include <stdbool.h>
#include <stdint.h>

#ifdef __cplusplus
extern "C" {
#endif

enum lock_hw_direction {
	LOCK_HW_DIR_LEFT = 0,
	LOCK_HW_DIR_RIGHT = 1,
};

enum lock_hw_switch {
	LOCK_HW_SW_POSITION, /* bolt position, follows the thumb-turn and the motor */
	LOCK_HW_SW_DIRECTION, /* handedness, set once by the installer but may be flipped any time */
};

/**
 * Called from the system work queue, after debouncing, whenever one of the
 * switches changes state.
 *
 * @param sw which switch changed.
 * @param active true when that switch now reads active.
 */
typedef void (*lock_hw_switch_cb_t)(enum lock_hw_switch sw, bool active);

/** Configure the motor outputs (off) and switch inputs, arm both switch interrupts. */
int lock_hw_init(lock_hw_switch_cb_t switch_cb);

/** Raw state of the bolt position switch. */
bool lock_hw_position_active(void);

/** Direction the motor must turn to lock, as selected by the handedness switch. */
enum lock_hw_direction lock_hw_lock_direction(void);

/** Opposite of @p dir. */
enum lock_hw_direction lock_hw_opposite(enum lock_hw_direction dir);

/** Derived bolt state: locked when the position switch agrees with the handedness switch. */
bool lock_hw_is_locked(void);

/** Enable the driver and run the motor at @p duty_percent (1..100) in @p dir. */
int lock_hw_motor_run(enum lock_hw_direction dir, uint8_t duty_percent);

/** Stop the motor and put the driver into standby. Safe to call when already stopped. */
int lock_hw_motor_stop(void);

bool lock_hw_motor_running(void);

#ifdef __cplusplus
}
#endif

#endif /* FARLOCK3_LOCK_HW_H */
```
